AUTOSAR XML (schema 00044)
package /VehicleProject
  system System
    root-software-compositions:
      root sw composition prototype EcuSwComposition: software-composition=ECU_Composition
package /ECUCompositionTypes
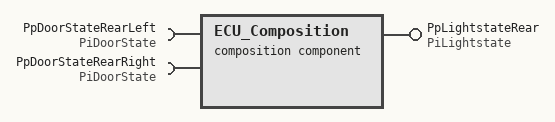
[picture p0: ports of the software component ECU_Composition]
  composition sw component type ECU_Composition
    require port PpDoorStateRearLeft: nonqueued-receiver-com-spec{data-element=DeDoorState, init-value=0}, required-interface=PiDoorState
    require port PpDoorStateRearRight: nonqueued-receiver-com-spec{data-element=DeDoorState, init-value=0}, required-interface=PiDoorState
    provide port PpLightstateRear: nonqueued-sender-com-spec{data-element=DeLightstate, init-value=0}, provided-interface=PiLightstate
    component CpCoApplication: type=CtCoApplication
    delegate CpCoApplication.PpDoorStateRearLeft <-> outer port PpDoorStateRearLeft
    delegate CpCoApplication.PpDoorStateRearRight <-> outer port PpDoorStateRearRight
    delegate CpCoApplication.PpLightstateRear <-> outer port PpLightstateRear
package /EndToEndProtections
  end to end protection set EndToEndProtectionSet
